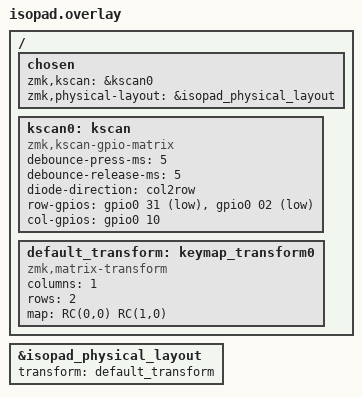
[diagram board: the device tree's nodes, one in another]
/*
 * 1-key Macropad Shield for NRF52840 Pro Micro
 * Uses GPIO 031 as the single key
 */
#include <dt-bindings/zmk/matrix_transform.h>
#include "isopad-layouts.dtsi"

&isopad_physical_layout {
    transform = <&default_transform>;
};

 / {
    chosen {
        zmk,kscan = &kscan0;
        zmk,physical-layout = &isopad_physical_layout;
    };

    kscan0: kscan {
        compatible = "zmk,kscan-gpio-matrix";
        debounce-press-ms = <5>;
        debounce-release-ms = <5>;

        diode-direction = "col2row";  // Column is output, row is input

        row-gpios = < &gpio0 31 (GPIO_ACTIVE_LOW | GPIO_PULL_UP) >,
                    < &gpio0 02 (GPIO_ACTIVE_LOW | GPIO_PULL_UP) >;

        col-gpios = < &gpio0 10 (GPIO_ACTIVE_HIGH) >;  // Column for Key 2
    };

    default_transform: keymap_transform0 {
        compatible = "zmk,matrix-transform";
        columns = <1>;
        rows = <2>;
        map = <
            RC(0,0)
            RC(1,0)
        >;
    };
};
